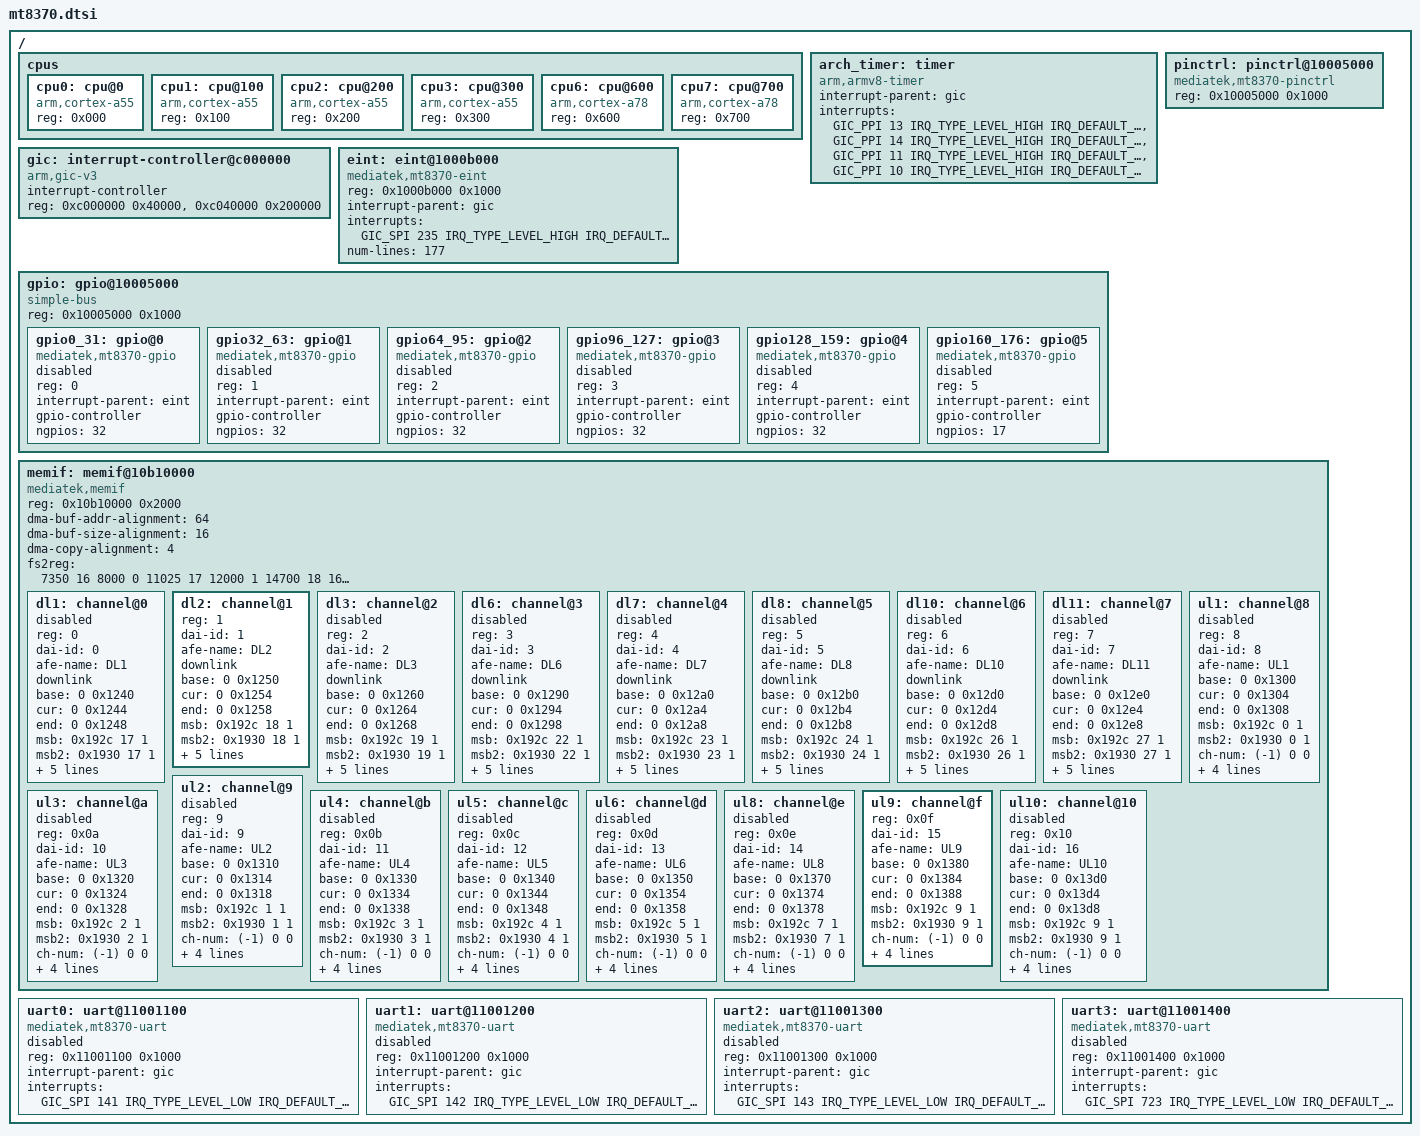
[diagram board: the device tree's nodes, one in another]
// SPDX-License-Identifier: GPL-2.0+
/*
 * Copyright (c) 2025 MediaTek Inc.
 *
 */

#include <arm64/armv8-a.dtsi>
#include <zephyr/dt-bindings/interrupt-controller/arm-gic.h>
#include <zephyr/dt-bindings/interrupt-controller/mtk-irq.h>


/ {
	#address-cells = <1>;
	#size-cells = <1>;

	cpus {
		#address-cells = <1>;
		#size-cells = <0>;

		cpu0: cpu@0 {
			device_type = "cpu";
			compatible = "arm,cortex-a55";
			reg = <0x000>;
		};

		cpu1: cpu@100 {
			device_type = "cpu";
			compatible = "arm,cortex-a55";
			reg = <0x100>;
		};

		cpu2: cpu@200 {
			device_type = "cpu";
			compatible = "arm,cortex-a55";
			reg = <0x200>;
		};

		cpu3: cpu@300 {
			device_type = "cpu";
			compatible = "arm,cortex-a55";
			reg = <0x300>;
		};

		cpu6: cpu@600 {
			device_type = "cpu";
			compatible = "arm,cortex-a78";
			reg = <0x600>;
		};

		cpu7: cpu@700 {
			device_type = "cpu";
			compatible = "arm,cortex-a78";
			reg = <0x700>;
		};
	};

	arch_timer: timer {
		compatible = "arm,armv8-timer";
		interrupt-parent = <&gic>;
		interrupts = <GIC_PPI 13 IRQ_TYPE_LEVEL_HIGH IRQ_DEFAULT_PRIORITY>,
				 <GIC_PPI 14 IRQ_TYPE_LEVEL_HIGH IRQ_DEFAULT_PRIORITY>,
				 <GIC_PPI 11 IRQ_TYPE_LEVEL_HIGH IRQ_DEFAULT_PRIORITY>,
				 <GIC_PPI 10 IRQ_TYPE_LEVEL_HIGH IRQ_DEFAULT_PRIORITY>;
	};

	gic: interrupt-controller@c000000 {
		compatible = "arm,gic-v3", "arm,gic";
		#interrupt-cells = <4>;
		interrupt-controller;
		reg = <0xc000000 0x40000>,
			  <0xc040000 0x200000>;
		status = "okay";
	};

	pinctrl: pinctrl@10005000 {
		compatible = "mediatek,mt8370-pinctrl";
		reg = <0x10005000 0x1000>;
		#address-cells = <1>;
		#size-cells = <0>;
		status = "okay";
	};

	eint: eint@1000b000 {
		compatible = "mediatek,mt8370-eint";
		reg = <0x1000b000 0x1000>;
		interrupt-parent = <&gic>;
		interrupts = <GIC_SPI 235 IRQ_TYPE_LEVEL_HIGH IRQ_DEFAULT_PRIORITY>;
		num-lines = <177>;	/* 225 */
		#address-cells = <1>;
		#size-cells = <0>;
		status = "okay";
	};

	gpio: gpio@10005000 {
		compatible = "simple-bus";
		reg = <0x10005000 0x1000>;
		#address-cells = <1>;
		#size-cells = <0>;

		gpio0_31: gpio@0 {
			compatible = "mediatek,mt8370-gpio";
			reg = <0>;
			interrupt-parent = <&eint>;
			gpio-controller;
			#gpio-cells = <2>;
			ngpios = <32>;
			status = "disabled";
		};

		gpio32_63: gpio@1 {
			compatible = "mediatek,mt8370-gpio";
			reg = <1>;
			interrupt-parent = <&eint>;
			gpio-controller;
			#gpio-cells = <2>;
			ngpios = <32>;
			status = "disabled";
		};

		gpio64_95: gpio@2 {
			compatible = "mediatek,mt8370-gpio";
			reg = <2>;
			interrupt-parent = <&eint>;
			gpio-controller;
			#gpio-cells = <2>;
			ngpios = <32>;
			status = "disabled";
		};

		gpio96_127: gpio@3 {
			compatible = "mediatek,mt8370-gpio";
			reg = <3>;
			interrupt-parent = <&eint>;
			gpio-controller;
			#gpio-cells = <2>;
			ngpios = <32>;
			status = "disabled";
		};

		gpio128_159: gpio@4 {
			compatible = "mediatek,mt8370-gpio";
			reg = <4>;
			interrupt-parent = <&eint>;
			gpio-controller;
			#gpio-cells = <2>;
			ngpios = <32>;
			status = "disabled";
		};

		gpio160_176: gpio@5 {
			compatible = "mediatek,mt8370-gpio";
			reg = <5>;
			interrupt-parent = <&eint>;
			gpio-controller;
			#gpio-cells = <2>;
			ngpios = <17>;
			status = "disabled";
		};
	};

	memif: memif@10b10000 {
		compatible = "mediatek,memif";
		reg = <0x10b10000 0x2000>;
		#address-cells = <1>;
		#size-cells = <0>;
		#dma-cells = <1>;
		dma-buf-addr-alignment = <64>;
		dma-buf-size-alignment = <16>;
		dma-copy-alignment = <4>;
		fs2reg = <7350 16  8000 0   11025 17   12000 1
			 14700 18  16000 2  22050 19   24000 3
			 29400 20  32000 4  44100 21   48000 5
			 88200 22  96000 6  176400 23  192000 7
			352800 24  384000 8>;
		status = "okay";

		dl1: channel@0 {
			reg = <0>;
			dai-id = <0>;
			afe-name = "DL1";
			downlink;
			base = <0 0x1240>;
			cur = <0 0x1244>;
			end = <0 0x1248>;
			msb = <0x192c 17 1>;
			msb2 = <0x1930 17 1>;
			ch-num = <0x124c 0 5>;
			hd = <0x124c 5 1>;
			fs = <0x15a0 5 5>;
			enable = <0x1200 17 1>;
			agent-disable = <0x0014 17 1>;
			status = "disabled";
		};
		dl2: channel@1 {
			reg = <1>;
			dai-id = <1>;
			afe-name = "DL2";
			downlink;
			base = <0 0x1250>;
			cur = <0 0x1254>;
			end = <0 0x1258>;
			msb = <0x192c 18 1>;
			msb2 = <0x1930 18 1>;
			ch-num = <0x125c 0 5>;
			hd = <0x125c 5 1>;
			fs = <0x15a0 10 5>;
			enable = <0x1200 18 1>;
			agent-disable = <0x0014 18 1>;
			status = "okay";
		};
		dl3: channel@2 {
			reg = <2>;
			dai-id = <2>;
			afe-name = "DL3";
			downlink;
			base = <0 0x1260>;
			cur = <0 0x1264>;
			end = <0 0x1268>;
			msb = <0x192c 19 1>;
			msb2 = <0x1930 19 1>;
			ch-num = <0x126c 0 5>;
			hd = <0x126c 5 1>;
			fs = <0x15a0 15 5>;
			enable = <0x1200 19 1>;
			agent-disable = <0x0014 19 1>;
			status = "disabled";
		};
		dl6: channel@3 {
			reg = <3>;
			dai-id = <3>;
			afe-name = "DL6";
			downlink;
			base = <0 0x1290>;
			cur = <0 0x1294>;
			end = <0 0x1298>;
			msb = <0x192c 22 1>;
			msb2 = <0x1930 22 1>;
			ch-num = <0x129c 0 5>;
			hd = <0x129c 5 1>;
			fs = <0x15a4 0 5>;
			enable = <0x1200 22 1>;
			agent-disable = <0x0014 22 1>;
			status = "disabled";
		};
		dl7: channel@4 {
			reg = <4>;
			dai-id = <4>;
			afe-name = "DL7";
			downlink;
			base = <0 0x12a0>;
			cur = <0 0x12a4>;
			end = <0 0x12a8>;
			msb = <0x192c 23 1>;
			msb2 = <0x1930 23 1>;
			ch-num = <0x12ac 0 5>;
			hd = <0x12ac 5 1>;
			fs = <(-1) 0 0>;
			enable = <0x1200 23 1>;
			agent-disable = <0x0014 23 1>;
			status = "disabled";
		};
		dl8: channel@5 {
			reg = <5>;
			dai-id = <5>;
			afe-name = "DL8";
			downlink;
			base = <0 0x12b0>;
			cur = <0 0x12b4>;
			end = <0 0x12b8>;
			msb = <0x192c 24 1>;
			msb2 = <0x1930 24 1>;
			ch-num = <0x12bc 0 6>;
			hd = <0x12bc 6 1>;
			fs = <0x15a4 10 5>;
			enable = <0x1200 24 1>;
			agent-disable = <0x0014 24 1>;
			status = "disabled";
		};
		dl10: channel@6 {
			reg = <6>;
			dai-id = <6>;
			afe-name = "DL10";
			downlink;
			base = <0 0x12d0>;
			cur = <0 0x12d4>;
			end = <0 0x12d8>;
			msb = <0x192c 26 1>;
			msb2 = <0x1930 26 1>;
			ch-num = <0x12dc 0 5>;
			hd = <0x12dc 5 1>;
			fs = <0x15a4 20 5>;
			enable = <0x1200 26 1>;
			agent-disable = <0x0014 26 1>;
			status = "disabled";
		};
		dl11: channel@7 {
			reg = <7>;
			dai-id = <7>;
			afe-name = "DL11";
			downlink;
			base = <0 0x12e0>;
			cur = <0 0x12e4>;
			end = <0 0x12e8>;
			msb = <0x192c 27 1>;
			msb2 = <0x1930 27 1>;
			ch-num = <0x12ec 0 7>;
			hd = <0x12ec 7 1>;
			fs = <0x15a4 25 5>;
			enable = <0x1200 27 1>;
			agent-disable = <0x0014 27 1>;
			status = "disabled";
		};
		ul1: channel@8 {
			reg = <8>;
			dai-id = <8>;
			afe-name = "UL1";
			base = <0 0x1300>;
			cur = <0 0x1304>;
			end = <0 0x1308>;
			msb = <0x192c 0 1>;
			msb2 = <0x1930 0 1>;
			ch-num = <(-1) 0 0>;
			hd = <0x130c 5 1>;
			fs = <(-1) 0 0>;
			enable = <0x1200 1 1>;
			agent-disable = <0x0014 0 1>;
			status = "disabled";
		};
		ul2: channel@9 {
			reg = <9>;
			dai-id = <9>;
			afe-name = "UL2";
			base = <0 0x1310>;
			cur = <0 0x1314>;
			end = <0 0x1318>;
			msb = <0x192c 1 1>;
			msb2 = <0x1930 1 1>;
			ch-num = <(-1) 0 0>;
			hd = <0x131c 5 1>;
			fs = <0x15a8 5 5>;
			enable = <0x1200 2 1>;
			agent-disable = <0x0014 1 1>;
			status = "disabled";
		};
		ul3: channel@a {
			reg = <0x0a>;
			dai-id = <10>;
			afe-name = "UL3";
			base = <0 0x1320>;
			cur = <0 0x1324>;
			end = <0 0x1328>;
			msb = <0x192c 2 1>;
			msb2 = <0x1930 2 1>;
			ch-num = <(-1) 0 0>;
			hd = <0x132c 5 1>;
			fs = <0x15a8 10 5>;
			enable = <0x1200 3 1>;
			agent-disable = <0x0014 2 1>;
			status = "disabled";
		};
		ul4: channel@b {
			reg = <0x0b>;
			dai-id = <11>;
			afe-name = "UL4";
			base = <0 0x1330>;
			cur = <0 0x1334>;
			end = <0 0x1338>;
			msb = <0x192c 3 1>;
			msb2 = <0x1930 3 1>;
			ch-num = <(-1) 0 0>;
			hd = <0x133c 5 1>;
			fs = <0x15a8 15 5>;
			enable = <0x1200 4 1>;
			agent-disable = <0x0014 3 1>;
			status = "disabled";
		};
		ul5: channel@c {
			reg = <0x0c>;
			dai-id = <12>;
			afe-name = "UL5";
			base = <0 0x1340>;
			cur = <0 0x1344>;
			end = <0 0x1348>;
			msb = <0x192c 4 1>;
			msb2 = <0x1930 4 1>;
			ch-num = <(-1) 0 0>;
			hd = <0x134c 5 1>;
			fs = <0x15a8 20 5>;
			enable = <0x1200 5 1>;
			agent-disable = <0x0014 4 1>;
			status = "disabled";
		};
		ul6: channel@d {
			reg = <0x0d>;
			dai-id = <13>;
			afe-name = "UL6";
			base = <0 0x1350>;
			cur = <0 0x1354>;
			end = <0 0x1358>;
			msb = <0x192c 5 1>;
			msb2 = <0x1930 5 1>;
			ch-num = <(-1) 0 0>;
			hd = <0x135c 5 1>;
			fs = <(-1) 0 0>;
			enable = <0x1200 6 1>;
			agent-disable = <0x0014 5 1>;
			status = "disabled";
		};
		ul8: channel@e {
			reg = <0x0e>;
			dai-id = <14>;
			afe-name = "UL8";
			base = <0 0x1370>;
			cur = <0 0x1374>;
			end = <0 0x1378>;
			msb = <0x192c 7 1>;
			msb2 = <0x1930 7 1>;
			ch-num = <(-1) 0 0>;
			hd = <0x137c 5 1>;
			fs = <0x15ac 5 5>;
			enable = <0x1200 8 1>;
			agent-disable = <0x0014 7 1>;
			status = "disabled";
		};
		ul9: channel@f {
			reg = <0x0f>;
			dai-id = <15>;
			afe-name = "UL9";
			base = <0 0x1380>;
			cur = <0 0x1384>;
			end = <0 0x1388>;
			msb = <0x192c 9 1>;
			msb2 = <0x1930 9 1>;
			ch-num = <(-1) 0 0>;
			hd = <0x138c 5 1>;
			fs = <0x15ac 10 5>;
			enable = <0x1200 9 1>;
			agent-disable = <0x0014 8 1>;
			status = "okay";
		};
		ul10: channel@10 {
			reg = <0x10>;
			dai-id = <16>;
			afe-name = "UL10";
			base = <0 0x13d0>;
			cur = <0 0x13d4>;
			end = <0 0x13d8>;
			msb = <0x192c 9 1>;
			msb2 = <0x1930 9 1>;
			ch-num = <(-1) 0 0>;
			hd = <0x13dc 5 1>;
			fs = <0x15ac 15 5>;
			enable = <0x1200 10 1>;
			agent-disable = <0x0014 9 1>;
			status = "disabled";
		};
	};

	uart0: uart@11001100 {
		compatible = "mediatek,mt8370-uart";
		reg = <0x11001100 0x1000>;
		interrupt-parent = <&gic>;
		interrupts = <GIC_SPI 141 IRQ_TYPE_LEVEL_LOW IRQ_DEFAULT_PRIORITY>;
		status = "disabled";
	};

	uart1: uart@11001200 {
		compatible = "mediatek,mt8370-uart";
		reg = <0x11001200 0x1000>;
		interrupt-parent = <&gic>;
		interrupts = <GIC_SPI 142 IRQ_TYPE_LEVEL_LOW IRQ_DEFAULT_PRIORITY>;
		status = "disabled";
	};

	uart2: uart@11001300 {
		compatible = "mediatek,mt8370-uart";
		reg = <0x11001300 0x1000>;
		interrupt-parent = <&gic>;
		interrupts = <GIC_SPI 143 IRQ_TYPE_LEVEL_LOW IRQ_DEFAULT_PRIORITY>;
		status = "disabled";
	};

	uart3: uart@11001400 {
		compatible = "mediatek,mt8370-uart";
		reg = <0x11001400 0x1000>;
		interrupt-parent = <&gic>;
		interrupts = <GIC_SPI 723 IRQ_TYPE_LEVEL_LOW IRQ_DEFAULT_PRIORITY>;
		status = "disabled";
	};
/*
	i2s: i2s@10b10000 {
		compatible = "mediatek,mt8370-i2s";
		reg = <0x10b10000 0x1000>;
		interrupt-parent = <&gic>;
		interrupts = <GIC_SPI 822 IRQ_TYPE_LEVEL_LOW IRQ_DEFAULT_PRIORITY>;
		status = "disabled";
	};
*/
};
